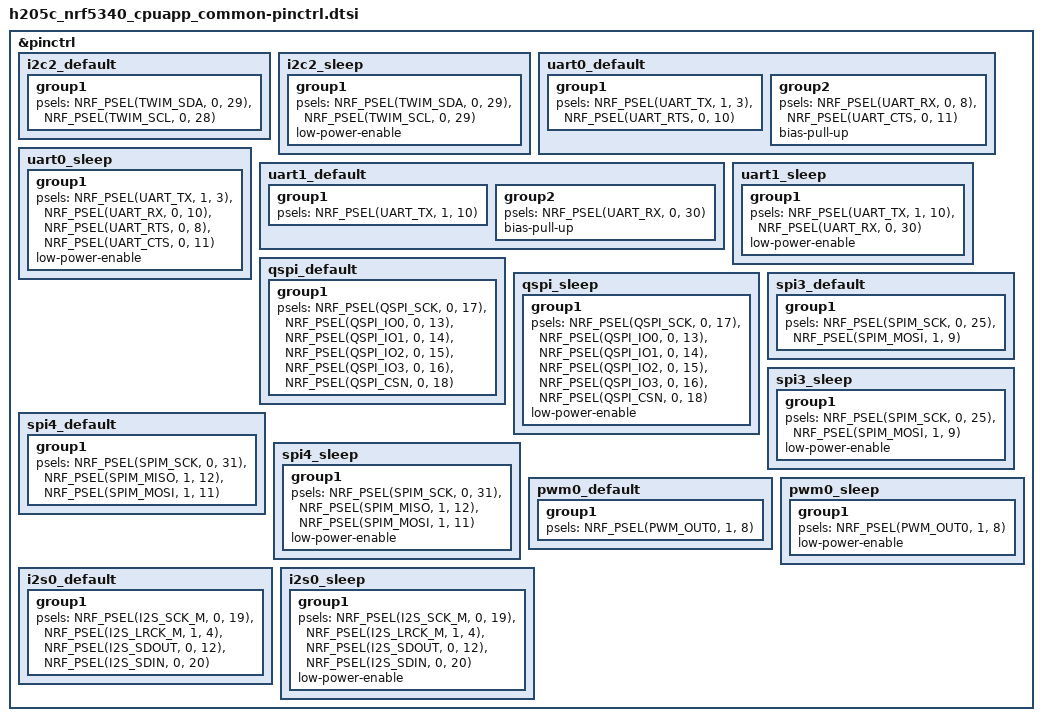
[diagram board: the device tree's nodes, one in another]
/*
 * Copyright (c) 2022 Acme CPU
 */

&pinctrl {
	i2c2_default: i2c2_default {
		group1 {
			psels = <NRF_PSEL(TWIM_SDA, 0, 29)>,
				<NRF_PSEL(TWIM_SCL, 0, 28)>;
		};
	};

	i2c2_sleep: i2c2_sleep {
		group1 {
			psels = <NRF_PSEL(TWIM_SDA, 0, 29)>,
				<NRF_PSEL(TWIM_SCL, 0, 29)>;
			low-power-enable;
		};
	};

	uart0_default: uart0_default {
		group1 {
			psels = <NRF_PSEL(UART_TX, 1, 3)>,
				<NRF_PSEL(UART_RTS, 0, 10)>;
		};
		group2 {
			psels = <NRF_PSEL(UART_RX, 0, 8)>,
				<NRF_PSEL(UART_CTS, 0, 11)>;
			bias-pull-up;
		};
	};

	uart0_sleep: uart0_sleep {
		group1 {
			psels = <NRF_PSEL(UART_TX, 1, 3)>,
				<NRF_PSEL(UART_RX, 0, 10)>,
				<NRF_PSEL(UART_RTS, 0, 8)>,
				<NRF_PSEL(UART_CTS, 0, 11)>;
			low-power-enable;
		};
	};

	uart1_default: uart1_default {
		group1 {
			psels = <NRF_PSEL(UART_TX, 1, 10)>;
		};
		group2 {
			psels = <NRF_PSEL(UART_RX, 0, 30)>;
			bias-pull-up;
		};
	};

	uart1_sleep: uart1_sleep {
		group1 {
			psels = <NRF_PSEL(UART_TX, 1, 10)>,
				<NRF_PSEL(UART_RX, 0, 30)>;
			low-power-enable;
		};
	};

	qspi_default: qspi_default {
		group1 {
			psels = <NRF_PSEL(QSPI_SCK, 0, 17)>,
				<NRF_PSEL(QSPI_IO0, 0, 13)>,
				<NRF_PSEL(QSPI_IO1, 0, 14)>,
				<NRF_PSEL(QSPI_IO2, 0, 15)>,
				<NRF_PSEL(QSPI_IO3, 0, 16)>,
				<NRF_PSEL(QSPI_CSN, 0, 18)>;
		};
	};

	qspi_sleep: qspi_sleep {
		group1 {
			psels = <NRF_PSEL(QSPI_SCK, 0, 17)>,
				<NRF_PSEL(QSPI_IO0, 0, 13)>,
				<NRF_PSEL(QSPI_IO1, 0, 14)>,
				<NRF_PSEL(QSPI_IO2, 0, 15)>,
				<NRF_PSEL(QSPI_IO3, 0, 16)>,
				<NRF_PSEL(QSPI_CSN, 0, 18)>;
			low-power-enable;
		};
	};

	spi3_default: spi3_default {
		group1 {
			psels = <NRF_PSEL(SPIM_SCK, 0, 25)>,
				/*<NRF_PSEL(SPIM_MISO, 1, 14)>,*/
				<NRF_PSEL(SPIM_MOSI, 1, 9)>;
		};
	};

	spi3_sleep: spi3_sleep {
		group1 {
			psels = <NRF_PSEL(SPIM_SCK, 0, 25)>,
				/*<NRF_PSEL(SPIM_MISO, 1, 14)>,*/
				<NRF_PSEL(SPIM_MOSI, 1, 9)>;
			low-power-enable;
		};
	};

	spi4_default: spi4_default {
		group1 {
			psels = <NRF_PSEL(SPIM_SCK, 0, 31)>,
				<NRF_PSEL(SPIM_MISO, 1, 12)>,
				<NRF_PSEL(SPIM_MOSI, 1, 11)>;
		};
	};

	spi4_sleep: spi4_sleep {
		group1 {
			psels = <NRF_PSEL(SPIM_SCK, 0, 31)>,
				<NRF_PSEL(SPIM_MISO, 1, 12)>,
				<NRF_PSEL(SPIM_MOSI, 1, 11)>;
			low-power-enable;
		};
	};

	pwm0_default: pwm0_default {
		group1 {
			psels = <NRF_PSEL(PWM_OUT0, 1, 8)>;
		};
	};

	pwm0_sleep: pwm0_sleep {
		group1 {
			psels = <NRF_PSEL(PWM_OUT0, 1, 8)>;
			low-power-enable;
		};
	};

	i2s0_default: i2s0_default {
		group1 {
			psels = <NRF_PSEL(I2S_SCK_M, 0, 19)>,
				<NRF_PSEL(I2S_LRCK_M, 1, 4)>,
				<NRF_PSEL(I2S_SDOUT, 0, 12)>,
				<NRF_PSEL(I2S_SDIN, 0, 20)>;
		};
	};

	i2s0_sleep: i2s0_sleep {
		group1 {
			psels = <NRF_PSEL(I2S_SCK_M, 0, 19)>,
				<NRF_PSEL(I2S_LRCK_M, 1, 4)>,
				<NRF_PSEL(I2S_SDOUT, 0, 12)>,
				<NRF_PSEL(I2S_SDIN, 0, 20)>;
			low-power-enable;
		};
	};
};
